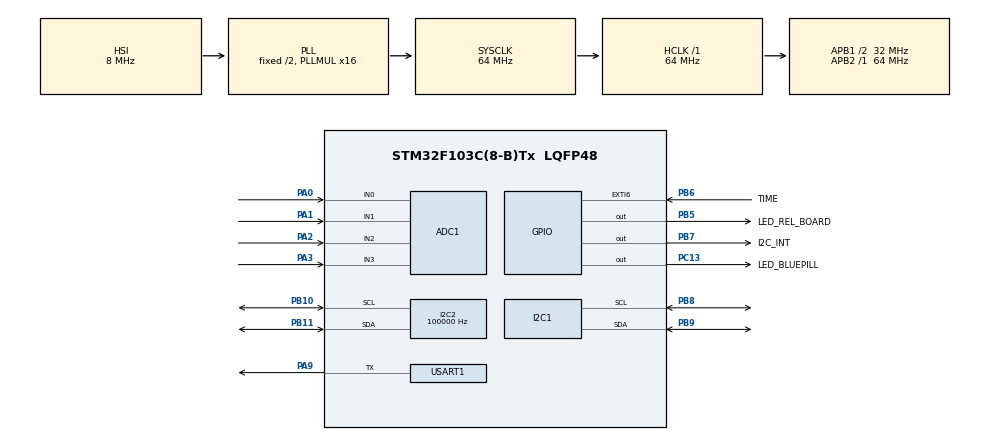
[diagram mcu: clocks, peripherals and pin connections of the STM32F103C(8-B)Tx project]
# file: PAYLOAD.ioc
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ADC1.EnableInjectedConversion=DISABLE
ADC1.EnableRegularConversion=DISABLE
ADC1.master=1
Dma.I2C1_RX.0.Direction=DMA_PERIPH_TO_MEMORY
Dma.I2C1_RX.0.Instance=DMA1_Channel7
Dma.I2C1_RX.0.MemDataAlignment=DMA_MDATAALIGN_BYTE
Dma.I2C1_RX.0.MemInc=DMA_MINC_ENABLE
Dma.I2C1_RX.0.Mode=DMA_NORMAL
Dma.I2C1_RX.0.PeriphDataAlignment=DMA_PDATAALIGN_BYTE
Dma.I2C1_RX.0.PeriphInc=DMA_PINC_DISABLE
Dma.I2C1_RX.0.Priority=DMA_PRIORITY_VERY_HIGH
Dma.I2C1_TX.1.Direction=DMA_MEMORY_TO_PERIPH
Dma.I2C1_TX.1.Instance=DMA1_Channel6
Dma.I2C1_TX.1.MemDataAlignment=DMA_MDATAALIGN_BYTE
Dma.I2C1_TX.1.MemInc=DMA_MINC_ENABLE
Dma.I2C1_TX.1.Mode=DMA_NORMAL
Dma.I2C1_TX.1.PeriphDataAlignment=DMA_PDATAALIGN_BYTE
Dma.I2C1_TX.1.PeriphInc=DMA_PINC_DISABLE
Dma.I2C1_TX.1.Priority=DMA_PRIORITY_VERY_HIGH
Dma.Request0=I2C1_RX
Dma.Request1=I2C1_TX
I2C1.I2C_Mode=I2C_Standard
I2C1.OwnAddress=0x68
I2C2.ClockSpeed=100000
I2C2.I2C_Mode=I2C_Standard
IWDG.Prescaler=IWDG_PRESCALER_128
IWDG.Reload=0xfff
Mcu.Family=STM32F1
Mcu.Name=STM32F103C(8-B)Tx
Mcu.Package=LQFP48
NVIC.DMA1_Channel6_IRQn=true\:0\:0\:false\:false\:true\:false\:true
NVIC.DMA1_Channel7_IRQn=true\:0\:0\:false\:false\:true\:false\:true
NVIC.EXTI9_5_IRQn=true\:0\:0\:false\:false\:true\:true\:true
NVIC.I2C1_ER_IRQn=true\:0\:0\:false\:false\:true\:true\:true
NVIC.I2C1_EV_IRQn=true\:0\:0\:false\:false\:true\:true\:true
NVIC.PriorityGroup=NVIC_PRIORITYGROUP_4
NVIC.TIM4_IRQn=true\:0\:0\:false\:false\:true\:true\:true
PA0-WKUP.Signal=ADCx_IN0
PA1.Signal=ADCx_IN1
PA13.Mode=Serial_Wire
PA13.Signal=SYS_JTMS-SWDIO
PA14.Mode=Serial_Wire
PA14.Signal=SYS_JTCK-SWCLK
PA2.Signal=ADCx_IN2
PA3.Signal=ADCx_IN3
PA9.Mode=Half_duplex(single_wire_mode)
PA9.Signal=USART1_TX
PB10.Mode=I2C
PB10.Signal=I2C2_SCL
PB11.Mode=I2C
PB11.Signal=I2C2_SDA
PB5.GPIO_Label=LED_REL_BOARD
PB5.GPIO_ModeDefaultOutputPP=GPIO_MODE_OUTPUT_OD
PB5.GPIO_Speed=GPIO_SPEED_FREQ_LOW
PB5.PinState=GPIO_PIN_SET
PB5.Signal=GPIO_Output
PB6.GPIO_Label=TIME
PB6.GPIO_ModeDefaultEXTI=GPIO_MODE_IT_RISING
PB6.GPIO_PuPd=GPIO_NOPULL
PB6.Signal=GPXTI6
PB7.GPIO_Label=I2C_INT
PB7.GPIO_ModeDefaultOutputPP=GPIO_MODE_OUTPUT_OD
PB7.GPIO_Speed=GPIO_SPEED_FREQ_HIGH
PB7.PinState=GPIO_PIN_SET
PB7.Signal=GPIO_Output
PB8.Mode=I2C
PB8.Signal=I2C1_SCL
PB9.Mode=I2C
PB9.Signal=I2C1_SDA
PC13-TAMPER-RTC.GPIO_Label=LED_BLUEPILL
PC13-TAMPER-RTC.GPIO_ModeDefaultOutputPP=GPIO_MODE_OUTPUT_OD
PC13-TAMPER-RTC.PinState=GPIO_PIN_SET
PC13-TAMPER-RTC.Signal=GPIO_Output
ProjectManager.HeapSize=0x200
ProjectManager.StackSize=0x400
ProjectManager.TargetToolchain=STM32CubeIDE
RCC.ADCPresc=RCC_ADCPCLK2_DIV6
RCC.AHBFreq_Value=64000000
RCC.APB1CLKDivider=RCC_HCLK_DIV2
RCC.APB1Freq_Value=32000000
RCC.APB1TimFreq_Value=64000000
RCC.APB2Freq_Value=64000000
RCC.APB2TimFreq_Value=64000000
RCC.HCLKFreq_Value=64000000
RCC.PLLMUL=RCC_PLL_MUL16
RCC.SYSCLKFreq_VALUE=64000000
RCC.SYSCLKSource=RCC_SYSCLKSOURCE_PLLCLK
RCC.USBFreq_Value=64000000
SH.ADCx_IN0.0=ADC1_IN0,IN0
SH.ADCx_IN1.0=ADC1_IN1,IN1
SH.ADCx_IN2.0=ADC1_IN2,IN2
SH.ADCx_IN3.0=ADC1_IN3,IN3
TIM4.Period=1999
TIM4.Prescaler=31999
USART1.Mode=MODE_TX
USART1.VirtualMode=VM_ASYNC
VP_ADC1_TempSens_Input.Mode=IN-TempSens
VP_IWDG_VS_IWDG.Mode=IWDG_Activate
VP_RTC_VS_RTC_Activate.Mode=RTC_Enabled
VP_TIM4_VS_ClockSourceINT.Mode=Internal
board=custom

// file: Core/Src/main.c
/* USER CODE BEGIN Header */
/**
  ******************************************************************************
  * @file           : main.c
  * @brief          : Main program body
  ******************************************************************************
  * @attention
  *
  * <h2><center>&copy; Copyright (c) 2020 STMicroelectronics.
  * All rights reserved.</center></h2>
  *
  * This software component is licensed by ST under BSD 3-Clause license,
  * the "License"; You may not use this file except in compliance with the
  * License. You may obtain a copy of the License at:
  *                        opensource.org/licenses/BSD-3-Clause
  *
  ******************************************************************************
  */
/* USER CODE END Header */
#include "main.h"

/* USER CODE BEGIN Includes */
#include <assert.h>
/* USER CODE END Includes */

ADC_HandleTypeDef hadc1;

I2C_HandleTypeDef hi2c1;
I2C_HandleTypeDef hi2c2;
DMA_HandleTypeDef hdma_i2c1_rx;
DMA_HandleTypeDef hdma_i2c1_tx;

IWDG_HandleTypeDef hiwdg;

TIM_HandleTypeDef htim4;

UART_HandleTypeDef huart1;

/* USER CODE BEGIN PV */

UART_HandleTypeDef huart1;
/* USER CODE END PV */

void SystemClock_Config(void);
static void MX_GPIO_Init(void);
static void MX_DMA_Init(void);
static void MX_I2C1_Init(void);
static void MX_I2C2_Init(void);
static void MX_ADC1_Init(void);
static void MX_IWDG_Init(void);
static void MX_TIM4_Init(void);
static void MX_RTC_Init(void);
static void MX_USART1_UART_Init(void);

/* USER CODE BEGIN 0 */
int app_main(void);
/* USER CODE END 0 */

int main(void)
{

  /* MCU Configuration--------------------------------------------------------*/

  /* Reset of all peripherals, Initializes the Flash interface and the Systick. */
  HAL_Init();

  /* Configure the system clock */
  SystemClock_Config();

  /* Initialize all configured peripherals */
  MX_GPIO_Init();
  MX_DMA_Init();
  MX_I2C1_Init();
  MX_I2C2_Init();
  MX_ADC1_Init();
  MX_IWDG_Init();
  MX_TIM4_Init();
  MX_RTC_Init();
  MX_USART1_UART_Init();
  /* USER CODE BEGIN 2 */
  app_main();
  /* USER CODE END 2 */

  /* Infinite loop */
  while (1)
  {

  }
}

void SystemClock_Config(void)
{
  RCC_OscInitTypeDef RCC_OscInitStruct = {0};
  RCC_ClkInitTypeDef RCC_ClkInitStruct = {0};
  RCC_PeriphCLKInitTypeDef PeriphClkInit = {0};

  /** Initializes the RCC Oscillators according to the specified parameters
  * in the RCC_OscInitTypeDef structure.
  */
  RCC_OscInitStruct.OscillatorType = RCC_OSCILLATORTYPE_HSI|RCC_OSCILLATORTYPE_LSI;
  RCC_OscInitStruct.HSIState = RCC_HSI_ON;
  RCC_OscInitStruct.HSICalibrationValue = RCC_HSICALIBRATION_DEFAULT;
  RCC_OscInitStruct.LSIState = RCC_LSI_ON;
  RCC_OscInitStruct.PLL.PLLState = RCC_PLL_ON;
  RCC_OscInitStruct.PLL.PLLSource = RCC_PLLSOURCE_HSI_DIV2;
  RCC_OscInitStruct.PLL.PLLMUL = RCC_PLL_MUL16;
  if (HAL_RCC_OscConfig(&RCC_OscInitStruct) != HAL_OK)
  {
    Error_Handler();
  }
  /** Initializes the CPU, AHB and APB buses clocks
  */
  RCC_ClkInitStruct.ClockType = RCC_CLOCKTYPE_HCLK|RCC_CLOCKTYPE_SYSCLK
                              |RCC_CLOCKTYPE_PCLK1|RCC_CLOCKTYPE_PCLK2;
  RCC_ClkInitStruct.SYSCLKSource = RCC_SYSCLKSOURCE_PLLCLK;
  RCC_ClkInitStruct.AHBCLKDivider = RCC_SYSCLK_DIV1;
  RCC_ClkInitStruct.APB1CLKDivider = RCC_HCLK_DIV2;
  RCC_ClkInitStruct.APB2CLKDivider = RCC_HCLK_DIV1;

  if (HAL_RCC_ClockConfig(&RCC_ClkInitStruct, FLASH_LATENCY_2) != HAL_OK)
  {
    Error_Handler();
  }
  PeriphClkInit.PeriphClockSelection = RCC_PERIPHCLK_RTC|RCC_PERIPHCLK_ADC;
  PeriphClkInit.RTCClockSelection = RCC_RTCCLKSOURCE_LSI;
  PeriphClkInit.AdcClockSelection = RCC_ADCPCLK2_DIV6;
  if (HAL_RCCEx_PeriphCLKConfig(&PeriphClkInit) != HAL_OK)
  {
    Error_Handler();
  }
}

static void MX_ADC1_Init(void)
{

  /** Common config
  */
  hadc1.Instance = ADC1;
  hadc1.Init.ScanConvMode = ADC_SCAN_DISABLE;
  hadc1.Init.ContinuousConvMode = DISABLE;
  hadc1.Init.DiscontinuousConvMode = DISABLE;
  hadc1.Init.ExternalTrigConv = ADC_SOFTWARE_START;
  hadc1.Init.DataAlign = ADC_DATAALIGN_RIGHT;
  hadc1.Init.NbrOfConversion = 1;
  if (HAL_ADC_Init(&hadc1) != HAL_OK)
  {
    Error_Handler();
  }

}

static void MX_I2C1_Init(void)
{

  hi2c1.Instance = I2C1;
  hi2c1.Init.ClockSpeed = 100000;
  hi2c1.Init.DutyCycle = I2C_DUTYCYCLE_2;
  hi2c1.Init.OwnAddress1 = 208;
  hi2c1.Init.AddressingMode = I2C_ADDRESSINGMODE_7BIT;
  hi2c1.Init.DualAddressMode = I2C_DUALADDRESS_DISABLE;
  hi2c1.Init.OwnAddress2 = 0;
  hi2c1.Init.GeneralCallMode = I2C_GENERALCALL_DISABLE;
  hi2c1.Init.NoStretchMode = I2C_NOSTRETCH_DISABLE;
  if (HAL_I2C_Init(&hi2c1) != HAL_OK)
  {
    Error_Handler();
  }

}

static void MX_I2C2_Init(void)
{

  hi2c2.Instance = I2C2;
  hi2c2.Init.ClockSpeed = 100000;
  hi2c2.Init.DutyCycle = I2C_DUTYCYCLE_2;
  hi2c2.Init.OwnAddress1 = 0;
  hi2c2.Init.AddressingMode = I2C_ADDRESSINGMODE_7BIT;
  hi2c2.Init.DualAddressMode = I2C_DUALADDRESS_DISABLE;
  hi2c2.Init.OwnAddress2 = 0;
  hi2c2.Init.GeneralCallMode = I2C_GENERALCALL_DISABLE;
  hi2c2.Init.NoStretchMode = I2C_NOSTRETCH_DISABLE;
  if (HAL_I2C_Init(&hi2c2) != HAL_OK)
  {
    Error_Handler();
  }

}

static void MX_IWDG_Init(void)
{

  /* USER CODE BEGIN IWDG_Init 1 */

  /* По поводу предделителя и релоада.
   * LSI в самом быстром случае бегает на 60 кГц.
   * В самом медленном - 30 кГц.
   * Если поставить предделитель в 128, а релоад в 0xFFF
   * Постчитаем
   * T_limit = 1/f * psc * reload;
   * для f = 60*10**3, T_limit = 8.736 секунды
   * для f = 30*10**3, T_limit = 17.472 секунды
   *
   * Вполне приемлемые цифры */
  /* USER CODE END IWDG_Init 1 */
  hiwdg.Instance = IWDG;
  hiwdg.Init.Prescaler = IWDG_PRESCALER_128;
  hiwdg.Init.Reload = 0xfff;
  if (HAL_IWDG_Init(&hiwdg) != HAL_OK)
  {
    Error_Handler();
  }
  /* USER CODE BEGIN IWDG_Init 2 */
#ifdef DEBUG
  // В режиме отладки IWDG стоит вместе с нами на брейкпоинтах
  // __HAL_DBGMCU_FREEZE_IWDG(); // Почему-то это вообще запарывает всю отладку
#endif
  /* USER CODE END IWDG_Init 2 */

}

static void MX_RTC_Init(void)
{

  /* USER CODE BEGIN RTC_Init 0 */

  // Мы используем RTC только для его крутых бэкап регистров, которые
  // хранят значения даже после System Reset-а
  // Поэтому так-то нам пофиг как оно там тикает
  // Мы это совсем не настраиваем

  /* USER CODE END RTC_Init 0 */

  LL_RTC_InitTypeDef RTC_InitStruct = {0};

    LL_PWR_EnableBkUpAccess();
    /* Enable BKP CLK enable for backup registers */
    LL_APB1_GRP1_EnableClock(LL_APB1_GRP1_PERIPH_BKP);
  /* Peripheral clock enable */
  LL_RCC_EnableRTC();

  /** Initialize RTC and set the Time and Date
  */
  RTC_InitStruct.AsynchPrescaler = 0xFFFFFFFFU;
  LL_RTC_Init(RTC, &RTC_InitStruct);
  LL_RTC_SetAsynchPrescaler(RTC, 0xFFFFFFFFU);

}

static void MX_TIM4_Init(void)
{

  TIM_ClockConfigTypeDef sClockSourceConfig = {0};
  TIM_MasterConfigTypeDef sMasterConfig = {0};

  htim4.Instance = TIM4;
  htim4.Init.Prescaler = 31999;
  htim4.Init.CounterMode = TIM_COUNTERMODE_UP;
  htim4.Init.Period = 1999;
  htim4.Init.ClockDivision = TIM_CLOCKDIVISION_DIV1;
  htim4.Init.AutoReloadPreload = TIM_AUTORELOAD_PRELOAD_DISABLE;
  if (HAL_TIM_Base_Init(&htim4) != HAL_OK)
  {
    Error_Handler();
  }
  sClockSourceConfig.ClockSource = TIM_CLOCKSOURCE_INTERNAL;
  if (HAL_TIM_ConfigClockSource(&htim4, &sClockSourceConfig) != HAL_OK)
  {
    Error_Handler();
  }
  sMasterConfig.MasterOutputTrigger = TIM_TRGO_RESET;
  sMasterConfig.MasterSlaveMode = TIM_MASTERSLAVEMODE_DISABLE;
  if (HAL_TIMEx_MasterConfigSynchronization(&htim4, &sMasterConfig) != HAL_OK)
  {
    Error_Handler();
  }

}

static void MX_USART1_UART_Init(void)
{

  huart1.Instance = USART1;
  huart1.Init.BaudRate = 115200;
  huart1.Init.WordLength = UART_WORDLENGTH_8B;
  huart1.Init.StopBits = UART_STOPBITS_1;
  huart1.Init.Parity = UART_PARITY_NONE;
  huart1.Init.Mode = UART_MODE_TX;
  huart1.Init.HwFlowCtl = UART_HWCONTROL_NONE;
  huart1.Init.OverSampling = UART_OVERSAMPLING_16;
  if (HAL_HalfDuplex_Init(&huart1) != HAL_OK)
  {
    Error_Handler();
  }

}

static void MX_DMA_Init(void)
{

  /* DMA controller clock enable */
  __HAL_RCC_DMA1_CLK_ENABLE();

  /* DMA interrupt init */
  /* DMA1_Channel6_IRQn interrupt configuration */
  HAL_NVIC_SetPriority(DMA1_Channel6_IRQn, 0, 0);
  HAL_NVIC_EnableIRQ(DMA1_Channel6_IRQn);
  /* DMA1_Channel7_IRQn interrupt configuration */
  HAL_NVIC_SetPriority(DMA1_Channel7_IRQn, 0, 0);
  HAL_NVIC_EnableIRQ(DMA1_Channel7_IRQn);

}

static void MX_GPIO_Init(void)
{
  GPIO_InitTypeDef GPIO_InitStruct = {0};

  /* GPIO Ports Clock Enable */
  __HAL_RCC_GPIOC_CLK_ENABLE();
  __HAL_RCC_GPIOA_CLK_ENABLE();
  __HAL_RCC_GPIOB_CLK_ENABLE();

  /*Configure GPIO pin Output Level */
  HAL_GPIO_WritePin(LED_BLUEPILL_GPIO_Port, LED_BLUEPILL_Pin, GPIO_PIN_SET);

  /*Configure GPIO pin Output Level */
  HAL_GPIO_WritePin(GPIOB, LED_REL_BOARD_Pin|I2C_INT_Pin, GPIO_PIN_SET);

  /*Configure GPIO pin : LED_BLUEPILL_Pin */
  GPIO_InitStruct.Pin = LED_BLUEPILL_Pin;
  GPIO_InitStruct.Mode = GPIO_MODE_OUTPUT_OD;
  GPIO_InitStruct.Pull = GPIO_NOPULL;
  GPIO_InitStruct.Speed = GPIO_SPEED_FREQ_LOW;
  HAL_GPIO_Init(LED_BLUEPILL_GPIO_Port, &GPIO_InitStruct);

  /*Configure GPIO pin : LED_REL_BOARD_Pin */
  GPIO_InitStruct.Pin = LED_REL_BOARD_Pin;
  GPIO_InitStruct.Mode = GPIO_MODE_OUTPUT_OD;
  GPIO_InitStruct.Pull = GPIO_NOPULL;
  GPIO_InitStruct.Speed = GPIO_SPEED_FREQ_LOW;
  HAL_GPIO_Init(LED_REL_BOARD_GPIO_Port, &GPIO_InitStruct);

  /*Configure GPIO pin : TIME_Pin */
  GPIO_InitStruct.Pin = TIME_Pin;
  GPIO_InitStruct.Mode = GPIO_MODE_IT_RISING;
  GPIO_InitStruct.Pull = GPIO_NOPULL;
  HAL_GPIO_Init(TIME_GPIO_Port, &GPIO_InitStruct);

  /*Configure GPIO pin : I2C_INT_Pin */
  GPIO_InitStruct.Pin = I2C_INT_Pin;
  GPIO_InitStruct.Mode = GPIO_MODE_OUTPUT_OD;
  GPIO_InitStruct.Pull = GPIO_NOPULL;
  GPIO_InitStruct.Speed = GPIO_SPEED_FREQ_HIGH;
  HAL_GPIO_Init(I2C_INT_GPIO_Port, &GPIO_InitStruct);

  /* EXTI interrupt init*/
  HAL_NVIC_SetPriority(EXTI9_5_IRQn, 0, 0);
  HAL_NVIC_EnableIRQ(EXTI9_5_IRQn);

}

/* USER CODE BEGIN 4 */

int _write(int fd, char* ptr, int len)
{
    (void)fd;
    HAL_UART_Transmit(&huart1, (uint8_t *)ptr, len, 100);
    return len;
}
/* USER CODE END 4 */

void Error_Handler(void)
{
  /* USER CODE BEGIN Error_Handler_Debug */
  /* User can add his own implementation to report the HAL error return state */
#ifdef DEBUG
  while(1) {}
#else
  assert(1 == 0);
#endif
  /* USER CODE END Error_Handler_Debug */
}

/************************ (C) COPYRIGHT STMicroelectronics *****END OF FILE****/
